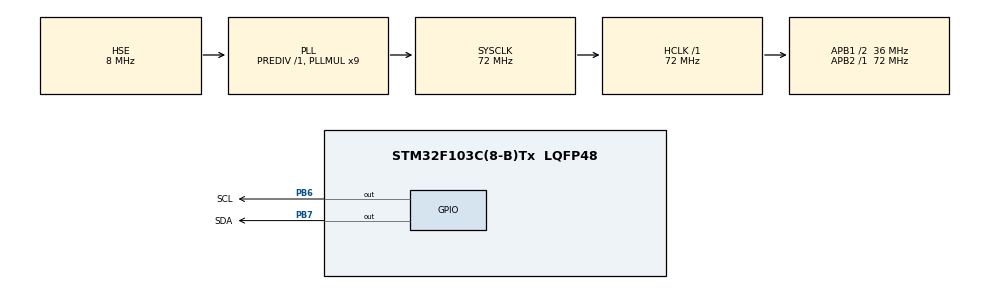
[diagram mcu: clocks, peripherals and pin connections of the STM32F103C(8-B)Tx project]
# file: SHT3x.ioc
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IWDG.Prescaler=IWDG_PRESCALER_64
IWDG.Reload=625
Mcu.Family=STM32F1
Mcu.Name=STM32F103C(8-B)Tx
Mcu.Package=LQFP48
NVIC.PriorityGroup=NVIC_PRIORITYGROUP_4
PB6.GPIO_Label=SCL
PB6.GPIO_ModeDefaultOutputPP=GPIO_MODE_OUTPUT_OD
PB6.GPIO_PuPd=GPIO_NOPULL
PB6.GPIO_Speed=GPIO_SPEED_FREQ_HIGH
PB6.PinState=GPIO_PIN_SET
PB6.Signal=GPIO_Output
PB7.GPIO_Label=SDA
PB7.GPIO_ModeDefaultOutputPP=GPIO_MODE_OUTPUT_OD
PB7.GPIO_PuPd=GPIO_NOPULL
PB7.GPIO_Speed=GPIO_SPEED_FREQ_HIGH
PB7.PinState=GPIO_PIN_SET
PB7.Signal=GPIO_Output
PC14-OSC32_IN.Mode=LSE-External-Oscillator
PC14-OSC32_IN.Signal=RCC_OSC32_IN
PC15-OSC32_OUT.Mode=LSE-External-Oscillator
PC15-OSC32_OUT.Signal=RCC_OSC32_OUT
PD0-OSC_IN.Mode=HSE-External-Oscillator
PD0-OSC_IN.Signal=RCC_OSC_IN
PD1-OSC_OUT.Mode=HSE-External-Oscillator
PD1-OSC_OUT.Signal=RCC_OSC_OUT
ProjectManager.HeapSize=0x200
ProjectManager.StackSize=0x400
ProjectManager.TargetToolchain=MDK-ARM V5.27
RCC.AHBFreq_Value=72000000
RCC.APB1CLKDivider=RCC_HCLK_DIV2
RCC.APB1Freq_Value=36000000
RCC.APB1TimFreq_Value=72000000
RCC.APB2Freq_Value=72000000
RCC.APB2TimFreq_Value=72000000
RCC.HCLKFreq_Value=72000000
RCC.PLLMUL=RCC_PLL_MUL9
RCC.PLLSourceVirtual=RCC_PLLSOURCE_HSE
RCC.SYSCLKFreq_VALUE=72000000
RCC.SYSCLKSource=RCC_SYSCLKSOURCE_PLLCLK
RCC.USBFreq_Value=72000000
VP_IWDG_VS_IWDG.Mode=IWDG_Activate
VP_SYS_VS_ND.Mode=No_Debug
board=custom

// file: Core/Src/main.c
/* USER CODE BEGIN Header */
/**
  ******************************************************************************
  * @file           : main.c
  * @brief          : Main program body
  ******************************************************************************
  * @attention
  *
  * Copyright (c) 2023 STMicroelectronics.
  * All rights reserved.
  *
  * This software is licensed under terms that can be found in the LICENSE file
  * in the root directory of this software component.
  * If no LICENSE file comes with this software, it is provided AS-IS.
  *
  ******************************************************************************
  */
/* USER CODE END Header */
#include "main.h"
#include "iwdg.h"
#include "gpio.h"

/* USER CODE BEGIN Includes */
#include "OLED.h"
#include "SHT3x.h"
/* USER CODE END Includes */

void SystemClock_Config(void);

  float Temp,Hum;			//声明变量存放温湿度数据
int main(void)
{
  /* USER CODE BEGIN 1 */
  uint32_t a=0;
	uint16_t err_count=0;
  /* USER CODE END 1 */

  /* MCU Configuration--------------------------------------------------------*/

  /* Reset of all peripherals, Initializes the Flash interface and the Systick. */
  HAL_Init();

  /* Configure the system clock */
  SystemClock_Config();

  /* Initialize all configured peripherals */
  MX_GPIO_Init();
  MX_IWDG_Init();

  /* USER CODE BEGIN 2 */
  OLED_Init();  //初始化OLED
  SHT3x_Init(); //初始化SHT3x
  uint8_t Chinese[]={0,1};
  OLED_ShowChinese(1,1,Chinese,2);//温度
  uint8_t Chinese1[]={2,3};
	OLED_ShowChinese(3,1,Chinese1,2);//湿度
  uint8_t Chinese2[]={4};
	OLED_ShowChinese(1,11,Chinese2,1);//℃
  /* USER CODE END 2 */

  /* Infinite loop */
  /* USER CODE BEGIN WHILE */
  while (1)
  {
    a++;
		OLED_ShowNum(2, 14, a, 2);
		if(a==99)a=0;

		if(ReadSHT3x(&Hum,&Temp))	//读取温湿度数据
		{
			if(Temp>=0)
			{
				char String[10];
				sprintf(String, "+%.2f", Temp);//格式化字符串输出到字符串变量
				OLED_ShowString(1, 5, String);	//显示温度

				sprintf(String, " %.2f%%", Hum);	//格式化字符串输出到字符串变量
				OLED_ShowString(3, 5, String);	//显示湿度
			}else
			{
				char String[10];
				sprintf(String, "%.2f", Temp);//格式化字符串输出到字符串变量
				OLED_ShowString(1, 5, String);	//显示温度

				sprintf(String, " %.2f%%", Hum);	//格式化字符串输出到字符串变量
				OLED_ShowString(3, 5, String);	//显示湿度
			}
		}
		else
		{
			err_count++;
			OLED_ShowNum(1,14, err_count, 2);	//显示错误次数计数
		}

	  /*
  	https://blog.zeruns.tech
	  */

		HAL_Delay(100);	//延时100毫秒
    /* USER CODE END WHILE */

    /* USER CODE BEGIN 3 */
    HAL_IWDG_Refresh(&hiwdg); //喂狗，重装看门狗计数值，避免复位
  }
  /* USER CODE END 3 */
}

void SystemClock_Config(void)
{
  RCC_OscInitTypeDef RCC_OscInitStruct = {0};
  RCC_ClkInitTypeDef RCC_ClkInitStruct = {0};

  /** Initializes the RCC Oscillators according to the specified parameters
  * in the RCC_OscInitTypeDef structure.
  */
  RCC_OscInitStruct.OscillatorType = RCC_OSCILLATORTYPE_LSI|RCC_OSCILLATORTYPE_HSE;
  RCC_OscInitStruct.HSEState = RCC_HSE_ON;
  RCC_OscInitStruct.HSEPredivValue = RCC_HSE_PREDIV_DIV1;
  RCC_OscInitStruct.HSIState = RCC_HSI_ON;
  RCC_OscInitStruct.LSIState = RCC_LSI_ON;
  RCC_OscInitStruct.PLL.PLLState = RCC_PLL_ON;
  RCC_OscInitStruct.PLL.PLLSource = RCC_PLLSOURCE_HSE;
  RCC_OscInitStruct.PLL.PLLMUL = RCC_PLL_MUL9;
  if (HAL_RCC_OscConfig(&RCC_OscInitStruct) != HAL_OK)
  {
    Error_Handler();
  }

  /** Initializes the CPU, AHB and APB buses clocks
  */
  RCC_ClkInitStruct.ClockType = RCC_CLOCKTYPE_HCLK|RCC_CLOCKTYPE_SYSCLK
                              |RCC_CLOCKTYPE_PCLK1|RCC_CLOCKTYPE_PCLK2;
  RCC_ClkInitStruct.SYSCLKSource = RCC_SYSCLKSOURCE_PLLCLK;
  RCC_ClkInitStruct.AHBCLKDivider = RCC_SYSCLK_DIV1;
  RCC_ClkInitStruct.APB1CLKDivider = RCC_HCLK_DIV2;
  RCC_ClkInitStruct.APB2CLKDivider = RCC_HCLK_DIV1;

  if (HAL_RCC_ClockConfig(&RCC_ClkInitStruct, FLASH_LATENCY_2) != HAL_OK)
  {
    Error_Handler();
  }
}

void Error_Handler(void)
{
  __disable_irq();
  while (1)
  {
  }
}
